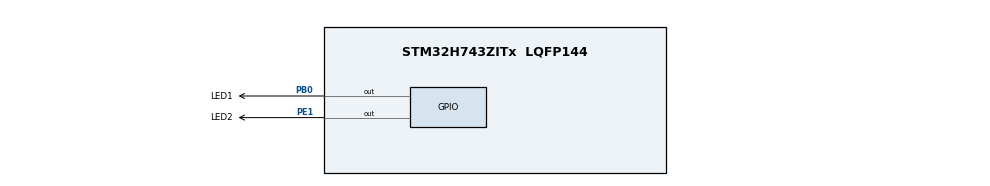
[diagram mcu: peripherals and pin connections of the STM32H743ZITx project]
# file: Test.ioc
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Mcu.Family=STM32H7
RCC.CortexFreq_Value=64000000
PB0.GPIO_Label=LED1
ProjectManager.StackSize=0x400
ProjectManager.TargetToolchain=STM32CubeIDE
RCC.HCLKFreq_Value=64000000
RCC.USBFreq_Value=129000000
PE1.Signal=GPIO_Output
board=custom
PE1.GPIO_Label=LED2
RCC.APB2Freq_Value=64000000
RCC.ADCFreq_Value=129000000
Mcu.Name=STM32H743ZITx
RCC.APB3Freq_Value=64000000
RCC.SYSCLKFreq_VALUE=64000000
Mcu.Package=LQFP144
ProjectManager.HeapSize=0x200
NVIC.PriorityGroup=NVIC_PRIORITYGROUP_4
RCC.APB4Freq_Value=64000000
RCC.APB1Freq_Value=64000000
PB0.Signal=GPIO_Output

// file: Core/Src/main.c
/* USER CODE BEGIN Header */
/**
  ******************************************************************************
  * @file           : main.c
  * @brief          : Main program bodypin_state = !pin_state;
// write pin state
// NOTE: You can in turn use HAL_GPIO_TogglePin
HAL_GPIO_WritePin(LED1_GPIO_Port, LED1_Pin, pin_state);
// synchronous delay for 500 ms
HAL_Delay(500);
  *
  ******************************************************************************
  * @attention
  *
  * <h2><center>&copy; Copyright (c) 2021 STMicroelectronics.
  * All rights reserved.</center></h2>
  *
  * This software component is licensed by ST under BSD 3-Clause license,
  * the "License"; You may not use this file except in compliance with the
  * License. You may obtain a copy of the License at:
  *                        opensource.org/licenses/BSD-3-Clause
  *
  ******************************************************************************
  */
/* USER CODE END Header */
#include "main.h"

void SystemClock_Config(void);
static void MX_GPIO_Init(void);

int main(void)
{

  /* MCU Configuration--------------------------------------------------------*/

  /* Reset of all peripherals, Initializes the Flash interface and the Systick. */
  HAL_Init();

  /* Configure the system clock */
  SystemClock_Config();

  /* Initialize all configured peripherals */
  MX_GPIO_Init();

  /* Infinite loop */
  /* USER CODE BEGIN WHILE */
  int pin_state = 0;
  while (1)
  {
    /* USER CODE END WHILE */
	  pin_state = !pin_state; //Change the state of the LED's
	  int pin_state_2 = !pin_state;
	  HAL_GPIO_WritePin(LED1_GPIO_Port, LED1_Pin, pin_state); //Write to LED_1
	  HAL_GPIO_WritePin(LED2_GPIO_Port, LED2_Pin, pin_state_2); //Write to LED_2
	  HAL_Delay(500); //Delay for 500ms

  }
}

void SystemClock_Config(void)
{
  RCC_OscInitTypeDef RCC_OscInitStruct = {0};
  RCC_ClkInitTypeDef RCC_ClkInitStruct = {0};

  /** Supply configuration update enable
  */
  HAL_PWREx_ConfigSupply(PWR_LDO_SUPPLY);
  /** Configure the main internal regulator output voltage
  */
  __HAL_PWR_VOLTAGESCALING_CONFIG(PWR_REGULATOR_VOLTAGE_SCALE3);

  while(!__HAL_PWR_GET_FLAG(PWR_FLAG_VOSRDY)) {}
  /** Initializes the RCC Oscillators according to the specified parameters
  * in the RCC_OscInitTypeDef structure.
  */
  RCC_OscInitStruct.OscillatorType = RCC_OSCILLATORTYPE_HSI;
  RCC_OscInitStruct.HSIState = RCC_HSI_DIV1;
  RCC_OscInitStruct.HSICalibrationValue = RCC_HSICALIBRATION_DEFAULT;
  RCC_OscInitStruct.PLL.PLLState = RCC_PLL_NONE;
  if (HAL_RCC_OscConfig(&RCC_OscInitStruct) != HAL_OK)
  {
    Error_Handler();
  }
  /** Initializes the CPU, AHB and APB buses clocks
  */
  RCC_ClkInitStruct.ClockType = RCC_CLOCKTYPE_HCLK|RCC_CLOCKTYPE_SYSCLK
                              |RCC_CLOCKTYPE_PCLK1|RCC_CLOCKTYPE_PCLK2
                              |RCC_CLOCKTYPE_D3PCLK1|RCC_CLOCKTYPE_D1PCLK1;
  RCC_ClkInitStruct.SYSCLKSource = RCC_SYSCLKSOURCE_HSI;
  RCC_ClkInitStruct.SYSCLKDivider = RCC_SYSCLK_DIV1;
  RCC_ClkInitStruct.AHBCLKDivider = RCC_HCLK_DIV1;
  RCC_ClkInitStruct.APB3CLKDivider = RCC_APB3_DIV1;
  RCC_ClkInitStruct.APB1CLKDivider = RCC_APB1_DIV1;
  RCC_ClkInitStruct.APB2CLKDivider = RCC_APB2_DIV1;
  RCC_ClkInitStruct.APB4CLKDivider = RCC_APB4_DIV1;

  if (HAL_RCC_ClockConfig(&RCC_ClkInitStruct, FLASH_LATENCY_1) != HAL_OK)
  {
    Error_Handler();
  }
}

static void MX_GPIO_Init(void)
{
  GPIO_InitTypeDef GPIO_InitStruct = {0};

  /* GPIO Ports Clock Enable */
  __HAL_RCC_GPIOB_CLK_ENABLE();
  __HAL_RCC_GPIOE_CLK_ENABLE();

  /*Configure GPIO pin Output Level */
  HAL_GPIO_WritePin(LED1_GPIO_Port, LED1_Pin, GPIO_PIN_RESET);

  /*Configure GPIO pin Output Level */
  HAL_GPIO_WritePin(LED2_GPIO_Port, LED2_Pin, GPIO_PIN_RESET);

  /*Configure GPIO pin : LED1_Pin */
  GPIO_InitStruct.Pin = LED1_Pin;
  GPIO_InitStruct.Mode = GPIO_MODE_OUTPUT_PP;
  GPIO_InitStruct.Pull = GPIO_NOPULL;
  GPIO_InitStruct.Speed = GPIO_SPEED_FREQ_LOW;
  HAL_GPIO_Init(LED1_GPIO_Port, &GPIO_InitStruct);

  /*Configure GPIO pin : LED2_Pin */
  GPIO_InitStruct.Pin = LED2_Pin;
  GPIO_InitStruct.Mode = GPIO_MODE_OUTPUT_PP;
  GPIO_InitStruct.Pull = GPIO_NOPULL;
  GPIO_InitStruct.Speed = GPIO_SPEED_FREQ_LOW;
  HAL_GPIO_Init(LED2_GPIO_Port, &GPIO_InitStruct);

}

void Error_Handler(void)
{
  __disable_irq();
  while (1)
  {
  }
}

/************************ (C) COPYRIGHT STMicroelectronics *****END OF FILE****/
